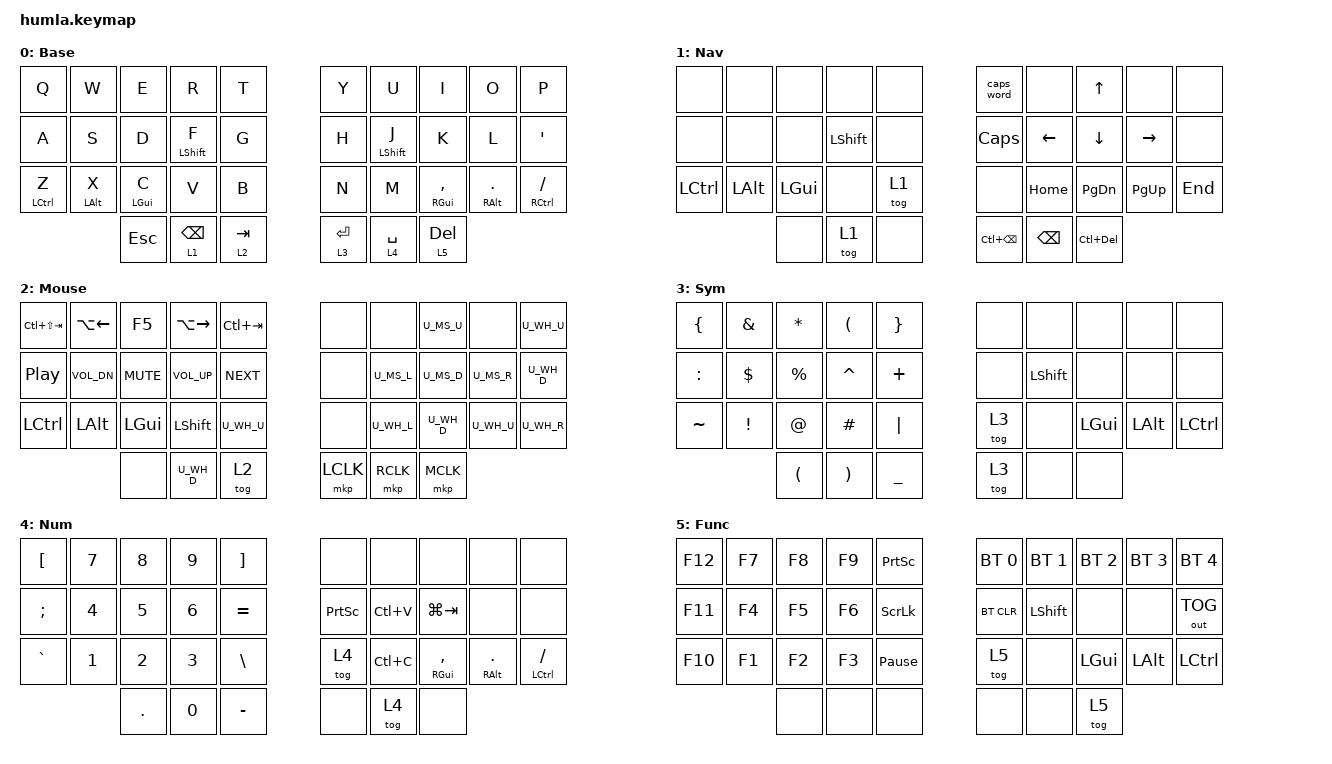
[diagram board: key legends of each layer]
/*
 * Copyright (c) 2020 The ZMK Contributors
 * SPDX-License-Identifier: MIT
 *
 * This is a QWERTY keymap for the Humla keyboard.
 * Last edited by Hans Lenze Kaper, 2024-04-21.
 */

#define ZMK_POINTING_DEFAULT_MOVE_VAL 1000  // default: 600
#define ZMK_POINTING_DEFAULT_SCRL_VAL 35    // default: 10

#include <behaviors.dtsi>
#include "mouse.dtsi"
#include <dt-bindings/zmk/keys.h>
#include <dt-bindings/zmk/bt.h>
#include <dt-bindings/zmk/outputs.h>
#include <dt-bindings/zmk/mouse.h>

/*
 * 0  1  2  3  4       5  6  7  8  9
 * Q  W  E  R  T       Y  U  I  O  P
 * 
 * 10 11 12 13 14      15 16 17 18 19
 * A  S  D  F  G       H  J  K  L  ;
 * 
 * 20 21 22 23 24      25 26 27 28 29
 * Z  X  C  V  B       N  M  ,  .  /
 */

 / {
    combos {
        compatible = "zmk,combos";
        
        capsword {
            layers = <0>;
            timeout-ms = <50>;
            key-positions = <11 12 17 18>;
            bindings = <&caps_word>;
        };
        combo_esc {
            layers = <0>;
            timeout-ms = <25>;
            key-positions = <0 1>;
            bindings = <&kp ESC>;
        };
        combo_lshift {
            layers = <0>;
            timeout-ms = <25>;
            key-positions = <11 12>;
            bindings = <&sk LSHIFT>;
        };
        combo_rshift {
            layers = <0>;
            timeout-ms = <25>;
            key-positions = <17 18>;
            bindings = <&sk RSHIFT>;
        };
        combo_mouselayer {
            layers = <0 2>;
            timeout-ms = <25>;
            key-positions = <3 4>;
            bindings = <&tog 2>;
        };
        combo_navlayer {
            layers = <0 1>;
            timeout-ms = <25>;
            key-positions = <13 14>;
            bindings = <&tog 1>;
        };
        combo_funlayer {
            layers = <0 5>;
            timeout-ms = <25>;
            key-positions = <5 6>;
            bindings = <&tog 5>;
        };
    };
};

&caps_word {
    continue-list = <UNDERSCORE MINUS DOT COMMA>;
};

&mt {
    tapping-term-ms = <250>;
    flavor = "tap-preferred";
    require-prior-idle-ms = <150>;
    quick-tap-ms = <175>;
};

&lt {
    tapping-term-ms = <230>;
    flavor = "balanced";
    require-prior-idle-ms = <100>;
    quick-tap-ms = <175>;
};

/ {
    keymap {
        compatible = "zmk,keymap";

        default_layer {
            label = "Base";
            bindings = <
                &kp Q          &kp W        &kp E       &kp R        &kp T           &kp Y       &kp U         &kp I           &kp O         &kp P
                &kp A          &kp S        &kp D       &mt LSHFT F  &kp G           &kp H       &mt LSHFT J   &kp K           &kp L         &kp SQT
                &mt LCTL Z     &mt LALT X   &mt LGUI C  &kp V        &kp B           &kp N       &kp M         &mt RGUI COMMA  &mt RALT DOT  &mt RCTL SLASH
                                            &kp ESC     &lt 1 BSPC   &lt 2 TAB       &lt 3 ENTER &lt 4 SPACE   &lt 5 DEL
            >;
        };

        nav_layer {
            label = "Nav";
            bindings = <
                &none       &none       &none       &none       &none       &caps_word     &none       &kp UP       &none       &none 
                &none       &none       &none       &kp LSHIFT  &none       &kp CAPS       &kp LEFT    &kp DOWN     &kp RIGHT   &none
                &kp LCTL    &kp LALT    &kp LGUI    &none       &tog 1      &none          &kp HOME    &kp PG_DN    &kp PG_UP   &kp END
                                        &none       &tog 1       &none       &kp LC(BSPC)  &kp BSPC    &kp LC(DEL)
            >;
        };

        mouse_layer {
            label = "Mouse";
            bindings = <
                &kp LC(LS(TAB)) &kp LA(LEFT)  &kp F5      &kp LA(RIGHT)   &kp LC(TAB)  &none       &none      U_MS_U     &none    U_WH_U 
                &kp C_PP        &kp C_VOL_DN  &kp C_MUTE  &kp C_VOL_UP    &kp C_NEXT   &none       U_MS_L     U_MS_D     U_MS_R   U_WH_D
                &kp LCTL        &kp LALT      &kp LGUI    &kp LSHIFT      U_WH_U       &none       U_WH_L     U_WH_D     U_WH_U   U_WH_R
                                              &none       U_WH_D          &tog 2       &mkp LCLK   &mkp RCLK  &mkp MCLK
            >;
        };
        
        sym_layer {
            label = "Sym";
            bindings = <
                &kp LBRC    &kp AMPS   &kp STAR   &kp LPAR   &kp RBRC         &none     &none       &none    &none    &none
                &kp COLON   &kp DLLR   &kp PRCNT  &kp CARET  &kp PLUS         &none     &kp LSHIFT  &none    &none    &none
                &kp TILDE   &kp EXCL   &kp AT     &kp HASH   &kp PIPE         &tog 3    &none       &kp LGUI &kp LALT &kp LCTL
                                       &kp LPAR   &kp RPAR   &kp UNDER        &tog 3    &none       &none
            >;
        };

        num_layer {
            label = "Num";
            bindings = <
                &kp LBKT   &kp N7   &kp N8   &kp N9   &kp RBKT         &none     &none       &none          &none         &none
                &kp SEMI   &kp N4   &kp N5   &kp N6   &kp EQUAL        &kp PSCRN &kp LC(V)   &kp LG(TAB)    &none         &none
                &kp GRAVE  &kp N1   &kp N2   &kp N3   &kp BACKSLASH    &tog 4    &kp LC(C)   &mt RGUI COMMA &mt RALT DOT  &mt LCTL SLASH
                                    &kp DOT  &kp N0   &kp MINUS        &none     &tog 4      &none
            >;
        };

        func_layer {
            label = "Func";
            bindings = <
                &kp F12   &kp F7  &kp F8    &kp F9     &kp PSCRN       &bt BT_SEL 0  &bt BT_SEL 1  &bt BT_SEL 2   &bt BT_SEL 3   &bt BT_SEL 4
                &kp F11   &kp F4  &kp F5    &kp F6     &kp SLCK        &bt BT_CLR    &kp LSHIFT    &none          &none          &out OUT_TOG
                &kp F10   &kp F1  &kp F2    &kp F3     &kp PAUSE_BREAK &tog 5        &none         &kp LGUI       &kp LALT       &kp LCTL
                                  &none     &none      &none           &none         &none         &tog 5
            >;
        };

    };
};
